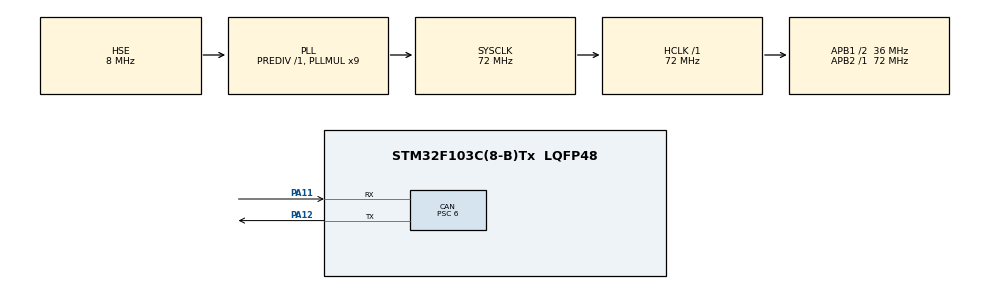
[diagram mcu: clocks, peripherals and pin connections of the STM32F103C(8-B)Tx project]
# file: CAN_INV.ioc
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CAN.BS1=CAN_BS1_8TQ
CAN.BS2=CAN_BS2_3TQ
CAN.CalculateBaudRate=500000
CAN.CalculateTimeBit=1999.99
CAN.CalculateTimeQuantum=166.66666666666669
CAN.Prescaler=6
Mcu.Family=STM32F1
Mcu.Name=STM32F103C(8-B)Tx
Mcu.Package=LQFP48
NVIC.PriorityGroup=NVIC_PRIORITYGROUP_4
NVIC.USB_LP_CAN1_RX0_IRQn=true\:0\:0\:false\:false\:true\:true\:true
PA11.Mode=CAN_Activate
PA11.Signal=CAN_RX
PA12.Mode=CAN_Activate
PA12.Signal=CAN_TX
PA13.Mode=Serial_Wire
PA13.Signal=SYS_JTMS-SWDIO
PA14.Mode=Serial_Wire
PA14.Signal=SYS_JTCK-SWCLK
PD0-OSC_IN.Mode=HSE-External-Oscillator
PD0-OSC_IN.Signal=RCC_OSC_IN
PD1-OSC_OUT.Mode=HSE-External-Oscillator
PD1-OSC_OUT.Signal=RCC_OSC_OUT
ProjectManager.HeapSize=0x200
ProjectManager.StackSize=0x400
ProjectManager.TargetToolchain=STM32CubeIDE
RCC.AHBFreq_Value=72000000
RCC.APB1CLKDivider=RCC_HCLK_DIV2
RCC.APB1Freq_Value=36000000
RCC.APB1TimFreq_Value=72000000
RCC.APB2Freq_Value=72000000
RCC.APB2TimFreq_Value=72000000
RCC.HCLKFreq_Value=72000000
RCC.PLLMUL=RCC_PLL_MUL9
RCC.PLLSourceVirtual=RCC_PLLSOURCE_HSE
RCC.SYSCLKFreq_VALUE=72000000
RCC.SYSCLKSource=RCC_SYSCLKSOURCE_PLLCLK
RCC.USBFreq_Value=72000000
board=custom

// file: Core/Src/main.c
/* USER CODE BEGIN Header */
/**
  ******************************************************************************
  * @file           : main.c
  * @brief          : Main program body
  ******************************************************************************
  * @attention
  *
  * <h2><center>&copy; Copyright (c) 2023 STMicroelectronics.
  * All rights reserved.</center></h2>
  *
  * This software component is licensed by ST under BSD 3-Clause license,
  * the "License"; You may not use this file except in compliance with the
  * License. You may obtain a copy of the License at:
  *                        opensource.org/licenses/BSD-3-Clause
  *
  ******************************************************************************
  */
/* USER CODE END Header */
#include "main.h"
#include "can.h"
#include "gpio.h"

void SystemClock_Config(void);

/* USER CODE BEGIN 0 */
CAN_TxHeaderTypeDef txHeader;
CAN_RxHeaderTypeDef rxHeader;
CAN_FilterTypeDef filterConfig;
uint32_t txMailbox;
uint8_t dummy = 0xFF;

volatile uint8_t cont_data[17];
volatile uint8_t tel_data[32];
volatile uint8_t flag_can = 1;

void Can_Send_Retrans(uint8_t* buffer){
	uint16_t cnt0;

	while(1){
		HAL_CAN_AddTxMessage(&hcan, &txHeader, &buffer[0], &txMailbox);
		cnt0 = HAL_GetTick();
		while(((HAL_GetTick() - cnt0) < 400) && flag_can == 1);
		if(flag_can == 0){
			flag_can = 1;
			break;
		}
	}
}

void Can_Config(){
	txHeader.IDE = CAN_ID_STD;
	txHeader.RTR = CAN_RTR_DATA;

	filterConfig.FilterFIFOAssignment = CAN_FILTER_FIFO0;
	filterConfig.FilterIdHigh = 0;
	filterConfig.FilterIdLow = 0;
	filterConfig.FilterMaskIdHigh = 0;
	filterConfig.FilterMaskIdLow = 0;
	filterConfig.FilterScale = CAN_FILTERSCALE_32BIT;
	filterConfig.FilterActivation = ENABLE;
	HAL_CAN_ConfigFilter(&hcan, &filterConfig);

	HAL_CAN_Start(&hcan);
	HAL_CAN_ActivateNotification(&hcan, CAN_IT_RX_FIFO0_MSG_PENDING);
}

void Inv_Read(uint8_t inv_id){
	uint8_t inv_com1[1] = {0x33};
	uint8_t inv_com2[1] = {0x37};

	txHeader.StdId = inv_id;
	txHeader.DLC = 1;
	Can_Send_Retrans(inv_com1);
	Can_Send_Retrans(inv_com2);
}

void HAL_CAN_RxFifo0MsgPendingCallback(CAN_HandleTypeDef *hcan){
	uint8_t can_rx_data[8];

	HAL_CAN_GetRxMessage(hcan, CAN_RX_FIFO0, &rxHeader, &can_rx_data[0]);

	switch(rxHeader.StdId){
		case 0x073:
			if(rxHeader.DLC == 6){
				tel_data[12] = can_rx_data[2];
			}
			if(rxHeader.DLC == 5){
				tel_data[13] = can_rx_data[0];
				tel_data[14] = can_rx_data[1];
				cont_data[4] = can_rx_data[3];
				cont_data[5] = can_rx_data[4];
			}
		break;

		case 0x074:
			if(rxHeader.DLC == 6){
				tel_data[15] = can_rx_data[2];
			}
			if(rxHeader.DLC == 5){
				tel_data[16] = can_rx_data[0];
				tel_data[17] = can_rx_data[1];
				cont_data[6] = can_rx_data[3];
				cont_data[7] = can_rx_data[4];
			}

		break;
	}

	flag_can = 0;
}
/* USER CODE END 0 */

int main(void)
{

  /* MCU Configuration--------------------------------------------------------*/

  /* Reset of all peripherals, Initializes the Flash interface and the Systick. */
  HAL_Init();

  /* Configure the system clock */
  SystemClock_Config();

  /* Initialize all configured peripherals */
  MX_GPIO_Init();
  MX_CAN_Init();
  /* USER CODE BEGIN 2 */
  Can_Config();
  /* USER CODE END 2 */

  /* Infinite loop */
  while (1)
  {
		Inv_Read(0x06B);
		Inv_Read(0x06C);
  }
}

void SystemClock_Config(void)
{
  RCC_OscInitTypeDef RCC_OscInitStruct = {0};
  RCC_ClkInitTypeDef RCC_ClkInitStruct = {0};

  /** Initializes the RCC Oscillators according to the specified parameters
  * in the RCC_OscInitTypeDef structure.
  */
  RCC_OscInitStruct.OscillatorType = RCC_OSCILLATORTYPE_HSE;
  RCC_OscInitStruct.HSEState = RCC_HSE_ON;
  RCC_OscInitStruct.HSEPredivValue = RCC_HSE_PREDIV_DIV1;
  RCC_OscInitStruct.HSIState = RCC_HSI_ON;
  RCC_OscInitStruct.PLL.PLLState = RCC_PLL_ON;
  RCC_OscInitStruct.PLL.PLLSource = RCC_PLLSOURCE_HSE;
  RCC_OscInitStruct.PLL.PLLMUL = RCC_PLL_MUL9;
  if (HAL_RCC_OscConfig(&RCC_OscInitStruct) != HAL_OK)
  {
    Error_Handler();
  }
  /** Initializes the CPU, AHB and APB buses clocks
  */
  RCC_ClkInitStruct.ClockType = RCC_CLOCKTYPE_HCLK|RCC_CLOCKTYPE_SYSCLK
                              |RCC_CLOCKTYPE_PCLK1|RCC_CLOCKTYPE_PCLK2;
  RCC_ClkInitStruct.SYSCLKSource = RCC_SYSCLKSOURCE_PLLCLK;
  RCC_ClkInitStruct.AHBCLKDivider = RCC_SYSCLK_DIV1;
  RCC_ClkInitStruct.APB1CLKDivider = RCC_HCLK_DIV2;
  RCC_ClkInitStruct.APB2CLKDivider = RCC_HCLK_DIV1;

  if (HAL_RCC_ClockConfig(&RCC_ClkInitStruct, FLASH_LATENCY_2) != HAL_OK)
  {
    Error_Handler();
  }
}

void Error_Handler(void)
{
  __disable_irq();
  while (1)
  {
  }
}

/************************ (C) COPYRIGHT STMicroelectronics *****END OF FILE****/
